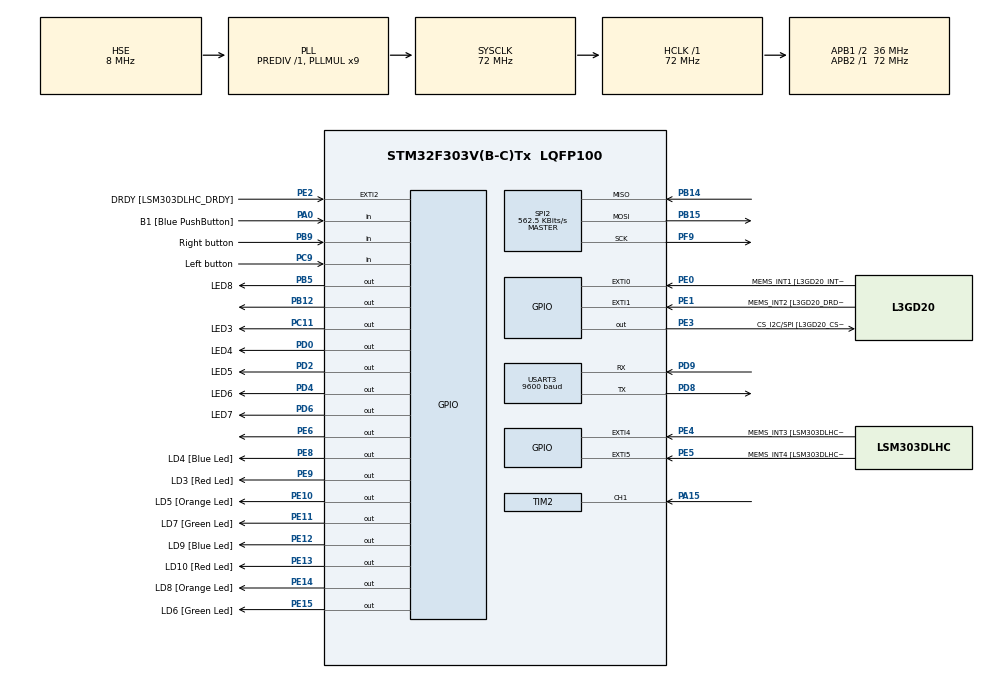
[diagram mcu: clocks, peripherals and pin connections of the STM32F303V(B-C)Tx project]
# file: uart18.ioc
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CRC.CRCLength=CRC_POLYLENGTH_8B
CRC.DefaultInitValueUse=DEFAULT_INIT_VALUE_DISABLE
CRC.DefaultPolynomialUse=DEFAULT_POLYNOMIAL_DISABLE
CRC.GeneratingPolynomial=X5+X4+X0
CRC.InputDataFormat=CRC_INPUTDATA_FORMAT_WORDS
CRC.InputDataInversionMode=CRC_INPUTDATA_INVERSION_NONE
Mcu.Family=STM32F3
Mcu.Name=STM32F303V(B-C)Tx
Mcu.Package=LQFP100
NVIC.PriorityGroup=NVIC_PRIORITYGROUP_0
NVIC.TIM2_IRQn=true\:0\:0\:false\:false\:true\:true\:true
NVIC.USART3_IRQn=true\:0\:0\:false\:false\:true\:true\:true
PA0.GPIO_Label=B1 [Blue PushButton]
PA0.GPIO_Mode=GPIO_MODE_INPUT
PA0.GPIO_PuPd=GPIO_NOPULL
PA0.Signal=GPIO_Input
PA11.GPIO_Label=DM
PA11.Signal=USB_DM
PA12.GPIO_Label=DP
PA12.Signal=USB_DP
PA13.GPIO_Label=SWDIO
PA13.Mode=Serial_Wire
PA13.Signal=SYS_JTMS-SWDIO
PA14.GPIO_Label=SWCLK
PA14.Mode=Serial_Wire
PA14.Signal=SYS_JTCK-SWCLK
PA15.Signal=S_TIM2_CH1_ETR
PA5.GPIO_Label=SPI1_SCK [L3GD20_SCL/SPC]
PA5.GPIO_Mode=GPIO_MODE_AF_PP
PA5.GPIO_PuPd=GPIO_NOPULL
PA5.GPIO_Speed=GPIO_SPEED_FREQ_LOW
PA5.Signal=SPI1_SCK
PA6.GPIO_Label=SPI1_MISO [L3GD20_SA0/SDO]
PA6.GPIO_Mode=GPIO_MODE_AF_PP
PA6.GPIO_PuPd=GPIO_NOPULL
PA6.GPIO_Speed=GPIO_SPEED_FREQ_LOW
PA6.Signal=SPI1_MISO
PA7.GPIO_Label=SPI1_MISO [L3GD20_SDA/SDI/SDO]
PA7.GPIO_Mode=GPIO_MODE_AF_PP
PA7.GPIO_PuPd=GPIO_NOPULL
PA7.GPIO_Speed=GPIO_SPEED_FREQ_LOW
PA7.Signal=SPI1_MOSI
PB12.Signal=GPIO_Output
PB14.Mode=Full_Duplex_Master
PB14.Signal=SPI2_MISO
PB15.Mode=Full_Duplex_Master
PB15.Signal=SPI2_MOSI
PB3.GPIO_Label=SWO
PB3.Signal=SYS_JTDO-TRACESWO
PB5.GPIO_Label=LED8
PB5.GPIO_Speed=GPIO_SPEED_FREQ_MEDIUM
PB5.Signal=GPIO_Output
PB6.GPIO_FM6=__NULL
PB6.GPIO_Label=I2C1_SCL [LSM303DLHC_SCL]
PB6.GPIO_Mode=GPIO_MODE_AF_OD
PB6.GPIO_PuPd=GPIO_NOPULL
PB6.GPIO_Speed=GPIO_SPEED_FREQ_LOW
PB6.Signal=I2C1_SCL
PB7.GPIO_FM7=__NULL
PB7.GPIO_Label=I2C1_SDA [LSM303DLHC_SDA]
PB7.GPIO_Mode=GPIO_MODE_AF_OD
PB7.GPIO_PuPd=GPIO_NOPULL
PB7.GPIO_Speed=GPIO_SPEED_FREQ_LOW
PB7.Signal=I2C1_SDA
PB9.GPIO_Label=Right button
PB9.Signal=GPIO_Input
PC11.GPIO_Label=LED3
PC11.GPIO_Speed=GPIO_SPEED_FREQ_MEDIUM
PC11.Signal=GPIO_Output
PC14-OSC32_IN.GPIO_Label=OSC32_IN
PC14-OSC32_IN.Signal=RCC_OSC32_IN
PC15-OSC32_OUT.GPIO_Label=OSC32_OUT
PC15-OSC32_OUT.Signal=RCC_OSC32_OUT
PC9.GPIO_Label=Left button
PC9.Signal=GPIO_Input
PD0.GPIO_Label=LED4
PD0.GPIO_Speed=GPIO_SPEED_FREQ_MEDIUM
PD0.Signal=GPIO_Output
PD2.GPIO_Label=LED5
PD2.GPIO_Speed=GPIO_SPEED_FREQ_MEDIUM
PD2.Signal=GPIO_Output
PD4.GPIO_Label=LED6
PD4.GPIO_Speed=GPIO_SPEED_FREQ_MEDIUM
PD4.Signal=GPIO_Output
PD6.GPIO_Label=LED7
PD6.GPIO_Speed=GPIO_SPEED_FREQ_MEDIUM
PD6.Signal=GPIO_Output
PD8.Mode=Asynchronous
PD8.Signal=USART3_TX
PD9.Mode=Asynchronous
PD9.Signal=USART3_RX
PE0.GPIO_Label=MEMS_INT1 [L3GD20_INT1]
PE0.GPIO_ModeDefaultEXTI=GPIO_MODE_EVT_RISING
PE0.GPIO_PuPd=GPIO_NOPULL
PE0.Signal=GPXTI0
PE1.GPIO_Label=MEMS_INT2 [L3GD20_DRDY/INT2]
PE1.GPIO_ModeDefaultEXTI=GPIO_MODE_EVT_RISING
PE1.GPIO_PuPd=GPIO_NOPULL
PE1.Signal=GPXTI1
PE10.GPIO_Label=LD5 [Orange Led]
PE10.GPIO_ModeDefaultOutputPP=GPIO_MODE_OUTPUT_PP
PE10.GPIO_PuPd=GPIO_NOPULL
PE10.GPIO_Speed=GPIO_SPEED_FREQ_LOW
PE10.Signal=GPIO_Output
PE11.GPIO_Label=LD7 [Green Led]
PE11.GPIO_ModeDefaultOutputPP=GPIO_MODE_OUTPUT_PP
PE11.GPIO_PuPd=GPIO_NOPULL
PE11.GPIO_Speed=GPIO_SPEED_FREQ_LOW
PE11.Signal=GPIO_Output
PE12.GPIO_Label=LD9 [Blue Led]
PE12.GPIO_ModeDefaultOutputPP=GPIO_MODE_OUTPUT_PP
PE12.GPIO_PuPd=GPIO_NOPULL
PE12.GPIO_Speed=GPIO_SPEED_FREQ_LOW
PE12.Signal=GPIO_Output
PE13.GPIO_Label=LD10 [Red Led]
PE13.GPIO_ModeDefaultOutputPP=GPIO_MODE_OUTPUT_PP
PE13.GPIO_PuPd=GPIO_NOPULL
PE13.GPIO_Speed=GPIO_SPEED_FREQ_LOW
PE13.Signal=GPIO_Output
PE14.GPIO_Label=LD8 [Orange Led]
PE14.GPIO_ModeDefaultOutputPP=GPIO_MODE_OUTPUT_PP
PE14.GPIO_PuPd=GPIO_NOPULL
PE14.GPIO_Speed=GPIO_SPEED_FREQ_LOW
PE14.Signal=GPIO_Output
PE15.GPIO_Label=LD6 [Green Led]
PE15.GPIO_ModeDefaultOutputPP=GPIO_MODE_OUTPUT_PP
PE15.GPIO_PuPd=GPIO_NOPULL
PE15.GPIO_Speed=GPIO_SPEED_FREQ_LOW
PE15.Signal=GPIO_Output
PE2.GPIO_Label=DRDY [LSM303DLHC_DRDY]
PE2.GPIO_ModeDefaultEXTI=GPIO_MODE_EVT_RISING
PE2.GPIO_PuPd=GPIO_NOPULL
PE2.Signal=GPXTI2
PE3.GPIO_Label=CS_I2C/SPI [L3GD20_CS_I2C/SPI]
PE3.GPIO_ModeDefaultOutputPP=GPIO_MODE_OUTPUT_PP
PE3.GPIO_PuPd=GPIO_NOPULL
PE3.GPIO_Speed=GPIO_SPEED_FREQ_LOW
PE3.Signal=GPIO_Output
PE4.GPIO_Label=MEMS_INT3 [LSM303DLHC_INT1]
PE4.GPIO_ModeDefaultEXTI=GPIO_MODE_EVT_RISING
PE4.GPIO_PuPd=GPIO_NOPULL
PE4.Signal=GPXTI4
PE5.GPIO_Label=MEMS_INT4 [LSM303DLHC_INT2]
PE5.GPIO_ModeDefaultEXTI=GPIO_MODE_EVT_RISING
PE5.GPIO_PuPd=GPIO_NOPULL
PE5.Signal=GPXTI5
PE6.Signal=GPIO_Output
PE8.GPIO_Label=LD4 [Blue Led]
PE8.GPIO_ModeDefaultOutputPP=GPIO_MODE_OUTPUT_PP
PE8.GPIO_PuPd=GPIO_NOPULL
PE8.GPIO_Speed=GPIO_SPEED_FREQ_LOW
PE8.Signal=GPIO_Output
PE9.GPIO_Label=LD3 [Red Led]
PE9.GPIO_ModeDefaultOutputPP=GPIO_MODE_OUTPUT_PP
PE9.GPIO_PuPd=GPIO_NOPULL
PE9.GPIO_Speed=GPIO_SPEED_FREQ_LOW
PE9.Signal=GPIO_Output
PF0-OSC_IN.Mode=HSE-External-Oscillator
PF0-OSC_IN.Signal=RCC_OSC_IN
PF1-OSC_OUT.GPIO_Label=OSC_OUT
PF1-OSC_OUT.Mode=HSE-External-Oscillator
PF1-OSC_OUT.Signal=RCC_OSC_OUT
PF9.Mode=Full_Duplex_Master
PF9.Signal=SPI2_SCK
ProjectManager.HeapSize=0x200
ProjectManager.StackSize=0x400
ProjectManager.TargetToolchain=EWARM V7
RCC.AHBFreq_Value=72000000
RCC.APB1CLKDivider=RCC_HCLK_DIV2
RCC.APB1Freq_Value=36000000
RCC.APB1TimFreq_Value=72000000
RCC.APB2Freq_Value=72000000
RCC.APB2TimFreq_Value=72000000
RCC.CortexFreq_Value=72000000
RCC.HCLKFreq_Value=72000000
RCC.HSE_VALUE=8000000
RCC.HSI_VALUE=8000000
RCC.LSE_VALUE=32768
RCC.PLLMUL=RCC_PLL_MUL9
RCC.PLLSourceVirtual=RCC_PLLSOURCE_HSE
RCC.SYSCLKFreq_VALUE=72000000
RCC.SYSCLKSourceVirtual=RCC_SYSCLKSOURCE_PLLCLK
RCC.USBFreq_Value=72000000
RTC.Format=RTC_FORMAT_BCD
SH.S_TIM2_CH1_ETR.0=TIM2_CH1,Input_Capture1_from_TI1
SH.S_TIM2_CH1_ETR.1=TIM2_CH1,Input_Capture2_from_TI1
SH.S_TIM2_CH1_ETR.2=TIM2_CH1,TriggerSource_TI1FP1
SPI2.BaudRatePrescaler=SPI_BAUDRATEPRESCALER_64
SPI2.CLKPhase=SPI_PHASE_2EDGE
SPI2.CLKPolarity=SPI_POLARITY_HIGH
SPI2.CRCCalculation=SPI_CRCCALCULATION_DISABLE
SPI2.CalculateBaudRate=562.5 KBits/s
SPI2.DataSize=SPI_DATASIZE_8BIT
SPI2.Direction=SPI_DIRECTION_2LINES
SPI2.FirstBit=SPI_FIRSTBIT_LSB
SPI2.Mode=SPI_MODE_MASTER
SPI2.VirtualType=VM_MASTER
TIM2.Channel-Input_Capture1_from_TI1=TIM_CHANNEL_1
TIM2.Channel-Input_Capture2_from_TI1=TIM_CHANNEL_2
TIM2.ICPolarity_CH2=TIM_INPUTCHANNELPOLARITY_FALLING
TIM2.Period=0xFFFF
TIM2.Prescaler=71
USART3.BaudRate=9600
USART3.VirtualMode-Asynchronous=VM_ASYNC
VP_CRC_VS_CRC.Mode=CRC_Activate
VP_RTC_VS_RTC_Activate.Mode=RTC_Enabled
VP_RTC_VS_RTC_Calendar.Mode=RTC_Calendar
VP_TIM2_VS_ClockSourceINT.Mode=Internal
VP_TIM2_VS_ControllerModeReset.Mode=Reset Mode
board=STM32F3DISCOVERY

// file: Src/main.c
/* USER CODE BEGIN Header */
/**
  ******************************************************************************
  * @file           : main.c
  * @brief          : Main program body
  ******************************************************************************
  * @attention
  *
  * <h2><center>&copy; Copyright (c) 2019 STMicroelectronics.
  * All rights reserved.</center></h2>
  *
  * This software component is licensed by ST under BSD 3-Clause license,
  * the "License"; You may not use this file except in compliance with the
  * License. You may obtain a copy of the License at:
  *                        opensource.org/licenses/BSD-3-Clause
  *
  ******************************************************************************
  */
/* USER CODE END Header */

#include "main.h"
#include "crc.h"
#include "rtc.h"
#include "spi.h"
#include "tim.h"
#include "usart.h"
#include "gpio.h"

void SystemClock_Config(void);

/* USER CODE BEGIN 0 */
void HAL_UART_TxCpltCallback(UART_HandleTypeDef *UartHandle){
  /* Set transmission flag: transfer complete*/
  UartReady = SET;
}

void HAL_UART_RxCpltCallback(UART_HandleTypeDef *UartHandle){
  /* Set transmission flag: transfer complete*/

  //Trying to set time instead of just showing it on display
  RTC_CalendarSet(RXBuffer);
  printf("%d\n", RXBuffer[0]);

  UartReady = SET;
}

/* USER CODE END 0 */

int main(void)
{
  /* USER CODE BEGIN 1 */
  uint_8 Tecken;
  char*hello = "Hello world!\n\r";
  /*USER CODE END 1 */

  /* MCU Configuration--------------------------------------------------------*/

  /* Reset of all peripherals, Initializes the Flash interface and the Systick. */
  HAL_Init();

  /* Configure the system clock */
  SystemClock_Config();

  /* Initialize all configured peripherals */
  MX_GPIO_Init();
  MX_USART3_UART_Init();
  MX_TIM2_Init();
  MX_CRC_Init();
  MX_SPI2_Init();
  MX_RTC_Init();
  /* USER CODE BEGIN 2 */
  HAL_UART_Transmit(&huart3, (uint8_t*)hello,strlen(hello),5000);
  /* USER CODE END 2 */

  /* Infinite loop */
  while (1)
  {
    HAL_UART_Receive(&huart3, &Tecken, 1, 5000);
    HAL_UART_Transmit(&huart3, &Tecken, 1, 5000);
  }
}

void SystemClock_Config(void)
{
  RCC_OscInitTypeDef RCC_OscInitStruct = {0};
  RCC_ClkInitTypeDef RCC_ClkInitStruct = {0};
  RCC_PeriphCLKInitTypeDef PeriphClkInit = {0};

  /** Initializes the CPU, AHB and APB busses clocks
  */
  RCC_OscInitStruct.OscillatorType = RCC_OSCILLATORTYPE_LSI|RCC_OSCILLATORTYPE_HSE;
  RCC_OscInitStruct.HSEState = RCC_HSE_ON;
  RCC_OscInitStruct.HSEPredivValue = RCC_HSE_PREDIV_DIV1;
  RCC_OscInitStruct.HSIState = RCC_HSI_ON;
  RCC_OscInitStruct.LSIState = RCC_LSI_ON;
  RCC_OscInitStruct.PLL.PLLState = RCC_PLL_ON;
  RCC_OscInitStruct.PLL.PLLSource = RCC_PLLSOURCE_HSE;
  RCC_OscInitStruct.PLL.PLLMUL = RCC_PLL_MUL9;
  if (HAL_RCC_OscConfig(&RCC_OscInitStruct) != HAL_OK)
  {
    Error_Handler();
  }
  /** Initializes the CPU, AHB and APB busses clocks
  */
  RCC_ClkInitStruct.ClockType = RCC_CLOCKTYPE_HCLK|RCC_CLOCKTYPE_SYSCLK
                              |RCC_CLOCKTYPE_PCLK1|RCC_CLOCKTYPE_PCLK2;
  RCC_ClkInitStruct.SYSCLKSource = RCC_SYSCLKSOURCE_PLLCLK;
  RCC_ClkInitStruct.AHBCLKDivider = RCC_SYSCLK_DIV1;
  RCC_ClkInitStruct.APB1CLKDivider = RCC_HCLK_DIV2;
  RCC_ClkInitStruct.APB2CLKDivider = RCC_HCLK_DIV1;

  if (HAL_RCC_ClockConfig(&RCC_ClkInitStruct, FLASH_LATENCY_2) != HAL_OK)
  {
    Error_Handler();
  }
  PeriphClkInit.PeriphClockSelection = RCC_PERIPHCLK_USART3|RCC_PERIPHCLK_RTC;
  PeriphClkInit.Usart3ClockSelection = RCC_USART3CLKSOURCE_PCLK1;
  PeriphClkInit.RTCClockSelection = RCC_RTCCLKSOURCE_LSI;
  if (HAL_RCCEx_PeriphCLKConfig(&PeriphClkInit) != HAL_OK)
  {
    Error_Handler();
  }
}

void Error_Handler(void)
{
}

/************************ (C) COPYRIGHT STMicroelectronics *****END OF FILE****/
